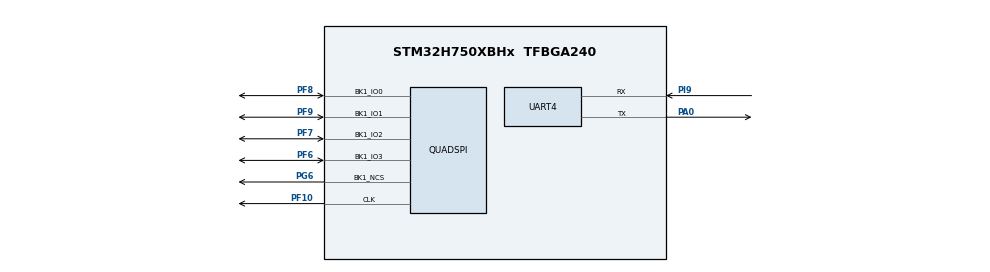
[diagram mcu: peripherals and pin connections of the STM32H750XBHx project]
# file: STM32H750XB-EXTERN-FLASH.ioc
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Mcu.Family=STM32H7
Mcu.Name=STM32H750XBHx
Mcu.Package=TFBGA240
NVIC.PriorityGroup=NVIC_PRIORITYGROUP_4
PA0.Mode=Asynchronous
PA0.Signal=UART4_TX
PA13\ (JTMS/SWDIO).Mode=Serial_Wire
PA13\ (JTMS/SWDIO).Signal=DEBUG_JTMS-SWDIO
PA14\ (JTCK/SWCLK).Mode=Serial_Wire
PA14\ (JTCK/SWCLK).Signal=DEBUG_JTCK-SWCLK
PF10.Mode=Single Bank 1
PF10.Signal=QUADSPI_CLK
PF6.Mode=Single Bank 1
PF6.Signal=QUADSPI_BK1_IO3
PF7.Mode=Single Bank 1
PF7.Signal=QUADSPI_BK1_IO2
PF8.Mode=Single Bank 1
PF8.Signal=QUADSPI_BK1_IO0
PF9.Mode=Single Bank 1
PF9.Signal=QUADSPI_BK1_IO1
PG6.Mode=Single Bank 1
PG6.Signal=QUADSPI_BK1_NCS
PH0-OSC_IN\ (PH0).Mode=HSE-External-Oscillator
PH0-OSC_IN\ (PH0).Signal=RCC_OSC_IN
PH1-OSC_OUT\ (PH1).Mode=HSE-External-Oscillator
PH1-OSC_OUT\ (PH1).Signal=RCC_OSC_OUT
PI9.Mode=Asynchronous
PI9.Signal=UART4_RX
ProjectManager.HeapSize=0x1000
ProjectManager.StackSize=0x1000
ProjectManager.TargetToolchain=STM32CubeIDE
QUADSPI.ChipSelectHighTime=QSPI_CS_HIGH_TIME_6_CYCLE
QUADSPI.ClockPrescaler=1
QUADSPI.FifoThreshold=4
QUADSPI.FlashSize=22
RCC.ADCFreq_Value=50390625
RCC.APB1Freq_Value=120000000
RCC.APB2Freq_Value=120000000
RCC.APB3Freq_Value=120000000
RCC.APB4Freq_Value=120000000
RCC.CortexFreq_Value=480000000
RCC.D1PPRE=RCC_APB3_DIV2
RCC.D2PPRE1=RCC_APB1_DIV2
RCC.D2PPRE2=RCC_APB2_DIV2
RCC.D3PPRE=RCC_APB4_DIV2
RCC.DIVM1=5
RCC.DIVN1=192
RCC.DIVR1=5
RCC.HCLKFreq_Value=240000000
RCC.HPRE=RCC_HCLK_DIV2
RCC.PLL2FRACN=0
RCC.PLL3FRACN=0
RCC.PLLSourceVirtual=RCC_PLLSOURCE_HSE
RCC.SYSCLKFreq_VALUE=480000000
RCC.SYSCLKSource=RCC_SYSCLKSOURCE_PLLCLK
RCC.USBFreq_Value=480000000
board=custom

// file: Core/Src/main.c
/* USER CODE BEGIN Header */
/**
  ******************************************************************************
  * @file           : main.c
  * @brief          : Main program body
  ******************************************************************************
  * @attention
  *
  * <h2><center>&copy; Copyright (c) 2021 STMicroelectronics.
  * All rights reserved.</center></h2>
  *
  * This software component is licensed by ST under BSD 3-Clause license,
  * the "License"; You may not use this file except in compliance with the
  * License. You may obtain a copy of the License at:
  *                        opensource.org/licenses/BSD-3-Clause
  *
  ******************************************************************************
  */
/* USER CODE END Header */
#include "main.h"
#include "quadspi.h"
#include "usart.h"
#include "gpio.h"

/* USER CODE BEGIN Includes */
#include "QSPI_XIP.h"
/* USER CODE END Includes */

void SystemClock_Config(void);

int main(void)
{

  /* MCU Configuration--------------------------------------------------------*/

  /* Reset of all peripherals, Initializes the Flash interface and the Systick. */
  HAL_Init();

  /* Configure the system clock */
  SystemClock_Config();

  /* Initialize all configured peripherals */
  MX_GPIO_Init();
  MX_QUADSPI_Init();
  MX_UART4_Init();

  /* Infinite loop */
  /* USER CODE BEGIN WHILE */
  TestStart();
  while (1)
  {
    /* USER CODE END WHILE */

    /* USER CODE BEGIN 3 */
	  Test();
	  HAL_Delay(550);
  }
  /* USER CODE END 3 */
}

void SystemClock_Config(void)
{
  RCC_OscInitTypeDef RCC_OscInitStruct = {0};
  RCC_ClkInitTypeDef RCC_ClkInitStruct = {0};
  RCC_PeriphCLKInitTypeDef PeriphClkInitStruct = {0};

  /** Supply configuration update enable
  */
  HAL_PWREx_ConfigSupply(PWR_LDO_SUPPLY);
  /** Configure the main internal regulator output voltage
  */
  __HAL_PWR_VOLTAGESCALING_CONFIG(PWR_REGULATOR_VOLTAGE_SCALE0);

  while(!__HAL_PWR_GET_FLAG(PWR_FLAG_VOSRDY)) {}
  /** Initializes the RCC Oscillators according to the specified parameters
  * in the RCC_OscInitTypeDef structure.
  */
  RCC_OscInitStruct.OscillatorType = RCC_OSCILLATORTYPE_HSE;
  RCC_OscInitStruct.HSEState = RCC_HSE_ON;
  RCC_OscInitStruct.PLL.PLLState = RCC_PLL_ON;
  RCC_OscInitStruct.PLL.PLLSource = RCC_PLLSOURCE_HSE;
  RCC_OscInitStruct.PLL.PLLM = 5;
  RCC_OscInitStruct.PLL.PLLN = 192;
  RCC_OscInitStruct.PLL.PLLP = 2;
  RCC_OscInitStruct.PLL.PLLQ = 2;
  RCC_OscInitStruct.PLL.PLLR = 5;
  RCC_OscInitStruct.PLL.PLLRGE = RCC_PLL1VCIRANGE_2;
  RCC_OscInitStruct.PLL.PLLVCOSEL = RCC_PLL1VCOWIDE;
  RCC_OscInitStruct.PLL.PLLFRACN = 0;
  if (HAL_RCC_OscConfig(&RCC_OscInitStruct) != HAL_OK)
  {
    Error_Handler();
  }
  /** Initializes the CPU, AHB and APB buses clocks
  */
  RCC_ClkInitStruct.ClockType = RCC_CLOCKTYPE_HCLK|RCC_CLOCKTYPE_SYSCLK
                              |RCC_CLOCKTYPE_PCLK1|RCC_CLOCKTYPE_PCLK2
                              |RCC_CLOCKTYPE_D3PCLK1|RCC_CLOCKTYPE_D1PCLK1;
  RCC_ClkInitStruct.SYSCLKSource = RCC_SYSCLKSOURCE_PLLCLK;
  RCC_ClkInitStruct.SYSCLKDivider = RCC_SYSCLK_DIV1;
  RCC_ClkInitStruct.AHBCLKDivider = RCC_HCLK_DIV2;
  RCC_ClkInitStruct.APB3CLKDivider = RCC_APB3_DIV2;
  RCC_ClkInitStruct.APB1CLKDivider = RCC_APB1_DIV2;
  RCC_ClkInitStruct.APB2CLKDivider = RCC_APB2_DIV2;
  RCC_ClkInitStruct.APB4CLKDivider = RCC_APB4_DIV2;

  if (HAL_RCC_ClockConfig(&RCC_ClkInitStruct, FLASH_LATENCY_4) != HAL_OK)
  {
    Error_Handler();
  }
  PeriphClkInitStruct.PeriphClockSelection = RCC_PERIPHCLK_UART4|RCC_PERIPHCLK_QSPI;
  PeriphClkInitStruct.QspiClockSelection = RCC_QSPICLKSOURCE_D1HCLK;
  PeriphClkInitStruct.Usart234578ClockSelection = RCC_USART234578CLKSOURCE_D2PCLK1;
  if (HAL_RCCEx_PeriphCLKConfig(&PeriphClkInitStruct) != HAL_OK)
  {
    Error_Handler();
  }
}

void Error_Handler(void)
{
  __disable_irq();
  while (1)
  {
  }
}

/************************ (C) COPYRIGHT STMicroelectronics *****END OF FILE****/
